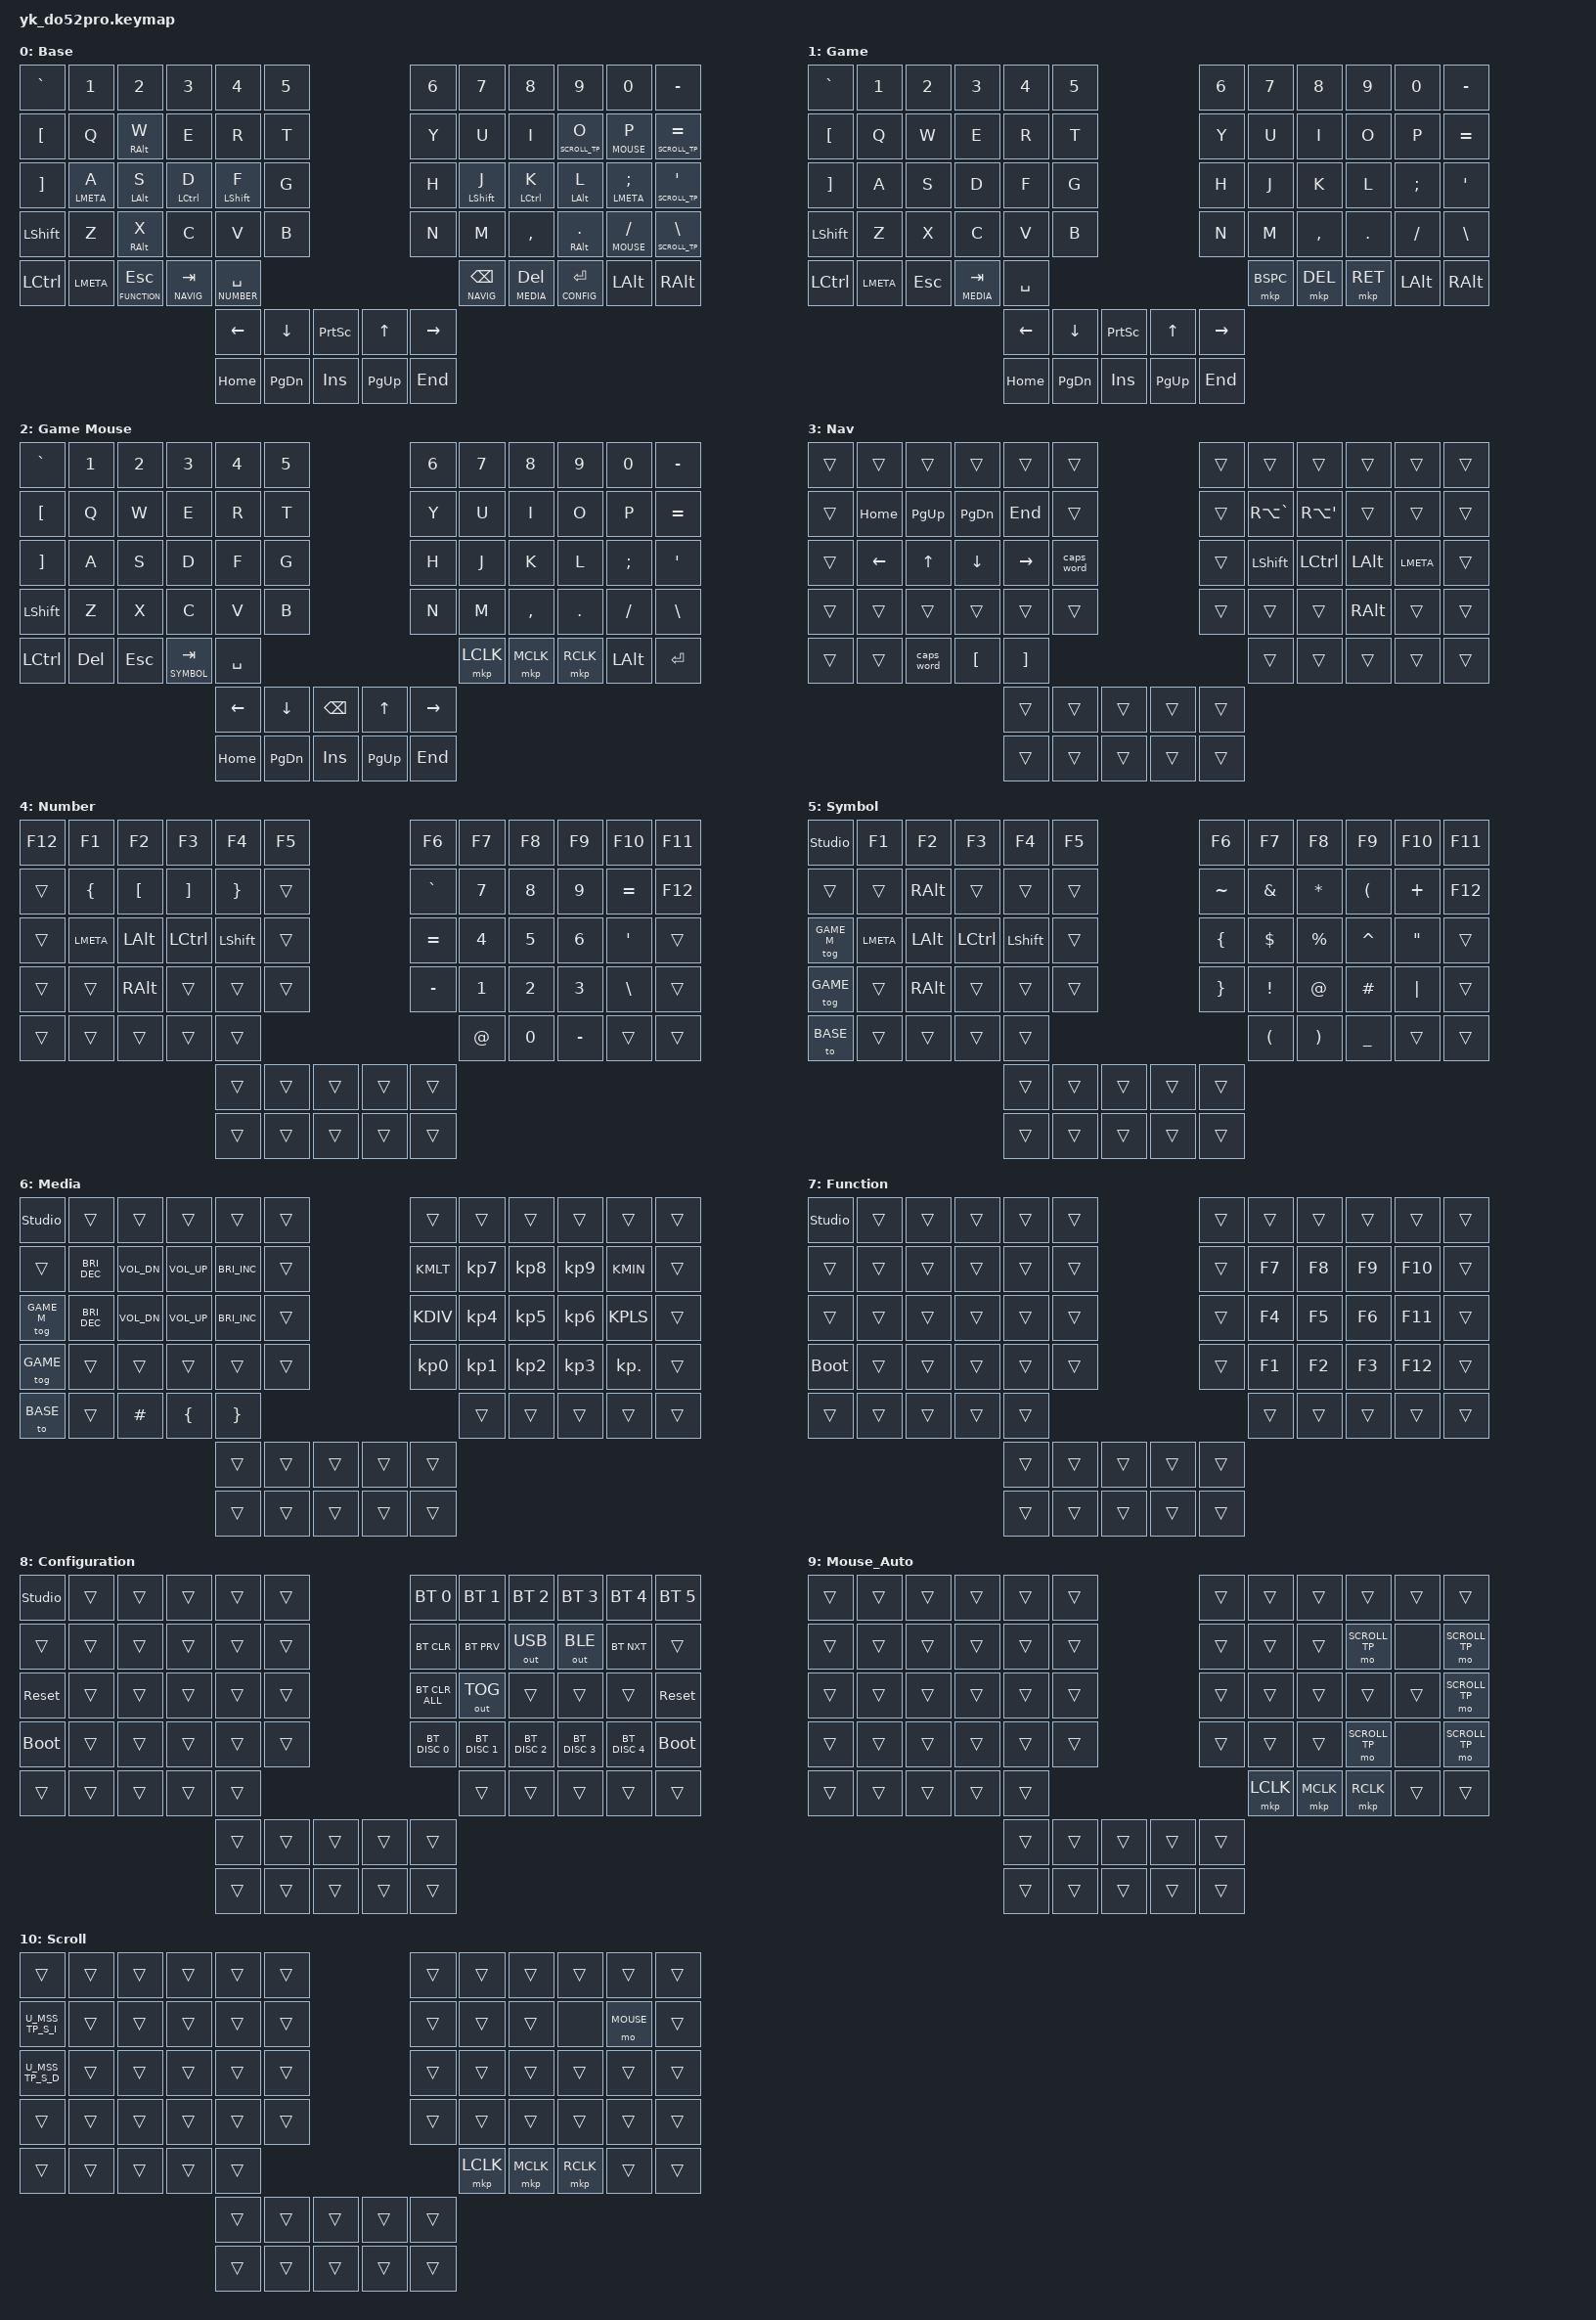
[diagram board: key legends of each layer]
/*
 * Copyright (c) 2020 The ZMK Contributors
 *
 * SPDX-License-Identifier: MIT
 */

#include <behaviors.dtsi>
#include <dt-bindings/zmk/keys.h>

#include "zmk-helpers/helper.h"
#include "include/yk_do52_key.h"                                     

#include <dt-bindings/zmk/bt.h>
#include <dt-bindings/zmk/ext_power.h>
#include <dt-bindings/zmk/outputs.h>


/*
 * Defines to enable/disable features
 *
 * These defines allow us to conditionally enable and disable parts of the keymap config.
 *
 * For example, if we decide to build the firmware without the mouse features, we can
 * disable all the config options that rely on those forks and modules without having
 * to edit the entire keymap file manually every time.
 */

#define HAS_MOUSE_KEYS
#define HAS_MOUSE_TP

#define BASE      0
#define GAME      1
#define GAME_M    2
#define NAVIG     3
#define NUMBER    4
#define SYMBOL    5
#define MEDIA     6
#define FUNCTION  7
#define CONFIG    8
#define MOUSE     9
#define SCROLL_TP 10

#ifdef HAS_MOUSE_KEYS
  #include <dt-bindings/zmk/mouse.h>
  #include <behaviors/mouse_keys.dtsi>
#endif  // HAS_MOUSE_KEYS

#ifdef HAS_MOUSE_TP
  // We store the trackpoint settings in a separate file
  // to make organization a little easier.
  #include "include/mouse_tp.dtsi"
#endif  // HAS_MOUSE_TP

// key-position labels
#define KEYS_L LT0 LT1 LT2 LT3 LT4 LM0 LM1 LM2 LM3 LM4 LB0 LB1 LB2 LB3 LB4  // left-hand keys
#define KEYS_R RT0 RT1 RT2 RT3 RT4 RM0 RM1 RM2 RM3 RM4 RB0 RB1 RB2 RB3 RB4  // right-hand keys
#define THUMBS LH4 LH3 LH2 LH1 LH0 RH0 RH1 RH2 RH3 RH4                      // thumb keys


// Adjust layer keys based on enabled features.
//
// This prevents build errors when we build the firmware
// without the mouse keys PR or the TP module.
#ifdef HAS_MOUSE_KEYS
  #define U_THUMB_INNER &mo MOUSE_KEYS
#else
  #define U_THUMB_INNER &none
#endif  // HAS_MOUSE_KEYS

#ifdef HAS_MOUSE_TP
  #define U_TOG_TP_SET &tog MOUSE_TP_SET
#else
  #define U_TOG_TP_SET &none
#endif  // HAS_MOUSE_TP


#define QUICK_TAP_MS 250


// Disable line-wrap in your editor to see a "visualization" of the key layouts
/ {

  
  behaviors {
       /* left-hand HRMs */
        hml: homerow_mods_left {
            compatible = "zmk,behavior-hold-tap";
            flavor = "balanced";
            tapping-term-ms = <280>;
            quick-tap-ms = <QUICK_TAP_MS>;                // repeat on tap-into-hold
            require-prior-idle-ms = <150>;
            #binding-cells = <2>;
            bindings = <&kp>, <&kp>;
            hold-trigger-key-positions = <KEYS_R THUMBS>;
            hold-trigger-on-release;             // delay positional check until key-release
        };

        /* right-hand HRMs */
        hmr: homerow_mods_right {
            compatible = "zmk,behavior-hold-tap";
            flavor = "balanced";
            tapping-term-ms = <280>;
            quick-tap-ms = <QUICK_TAP_MS>;                // repeat on tap-into-hold
            require-prior-idle-ms = <150>;
            #binding-cells = <2>;
            bindings = <&kp>, <&kp>;
            hold-trigger-key-positions = <KEYS_L THUMBS>;
            hold-trigger-on-release;             // delay positional check until key-release
        };
        tl: thumb_layer {
            compatible = "zmk,behavior-hold-tap";
             flavor = "balanced";
            tapping-term-ms = <280>;
            quick-tap-ms = <QUICK_TAP_MS>;                // repeat on tap-into-hold
            require-prior-idle-ms = <150>;
            #binding-cells = <2>;
            bindings = <&mo>, <&kp>;
            hold-trigger-on-release;             // delay positional check until key-release
        };       
  };
  //0
  keymap {
    compatible = "zmk,keymap";
   
    Base_layer {
      display-name = "Base";
      bindings = <
//|-----------------|-------------|-----------|------------|-----------------|----------------|---------------|   |---------------|---------------|-------------|------------|---------------|---------------|-------------|
   &kp GRAVE         &kp N1        &kp N2      &kp N3       &kp N4            &kp N5                                               &kp N6          &kp N7        &kp N8       &kp N9          &kp N0          &kp MINUS
   &kp LBKT          &kp Q         &hml RALT W &kp E        &kp R             &kp T                                                &kp Y           &kp U         &kp I        &tl SCROLL_TP O &tl MOUSE P     &tl SCROLL_TP EQUAL
   &kp RBKT          &hml LMETA A  &hml LALT S &hml LCTRL D &hml LSHIFT F     &kp G                                                &kp H           &hml LSHIFT J &hmr LCTRL K &hmr LALT L     &hmr LMETA SEMI &tl SCROLL_TP SQT
   &kp LSHFT         &kp Z         &hml RALT X &kp C        &kp V             &kp B                                                &kp N           &kp M         &kp COMMA    &hmr RALT DOT   &tl MOUSE FSLH  &tl SCROLL_TP BSLH
   &kp LCTRL         &kp LMETA                              &tl FUNCTION ESC  &tl NAVIG TAB   &tl NUMBER SPACE    &tl NAVIG BSPC  &tl MEDIA DEL   &tl CONFIG RET                             &kp LALT        &kp RALT
                                             // DPAD  Left,     Down,      Middle,     Up,        Right
                                                      &kp LEFT  &kp DOWN   &kp PSCRN   &kp UP     &kp RIGHT
                                                      &kp HOME  &kp PG_DN  &kp INS     &kp PG_UP  &kp END
      >;
    };
//1
      Game_layer {
      display-name = "Game";
      bindings = <
//|-----------------|-------------|-----------|------------|-----------------|----------------|--------------|   |---------------|---------------|-------------|-----------|-------------|---------------|------------|
   &kp GRAVE         &kp N1        &kp N2      &kp N3       &kp N4            &kp N5                                              &kp N6          &kp N7        &kp N8       &kp N9          &kp N0          &kp MINUS
   &kp LBKT          &kp Q         &kp W       &kp E        &kp R             &kp T                                               &kp Y           &kp U         &kp I        &kp O           &kp P           &kp EQUAL
   &kp RBKT          &kp A         &kp S       &kp D        &kp F             &kp G                                               &kp H           &kp J         &kp K        &kp L           &kp SEMI        &kp SQT
   &kp LSHFT         &kp Z         &kp X       &kp C        &kp V             &kp B                                               &kp N           &kp M         &kp COMMA    &kp DOT         &kp FSLH        &kp BSLH
   &kp LCTRL         &kp LMETA                              &kp ESC           &tl MEDIA TAB   &kp SPACE           &mkp BSPC      &mkp DEL        &mkp RET                                   &kp LALT        &kp RALT
                                             // DPAD  Left,     Down,      Middle,     Up,        ,Right
                                                      &kp LEFT  &kp DOWN   &kp PSCRN   &kp UP     &kp RIGHT
                                                      &kp HOME  &kp PG_DN  &kp INS     &kp PG_UP  &kp END
      >;
    };
//2
      GameMouse_layer {
      display-name = "Game Mouse";
      bindings = <
//|-----------------|-------------|-----------|------------|-----------------|----------------|--------------|   |---------------|---------------|-------------|-----------|-------------|---------------|------------|
   &kp GRAVE         &kp N1        &kp N2      &kp N3       &kp N4            &kp N5                                              &kp N6          &kp N7        &kp N8       &kp N9          &kp N0          &kp MINUS
   &kp LBKT          &kp Q         &kp W       &kp E        &kp R             &kp T                                               &kp Y           &kp U         &kp I        &kp O           &kp P           &kp EQUAL
   &kp RBKT          &kp A         &kp S       &kp D        &kp F             &kp G                                               &kp H           &kp J         &kp K        &kp L           &kp SEMI        &kp SQT
   &kp LSHFT         &kp Z         &kp X       &kp C        &kp V             &kp B                                               &kp N           &kp M         &kp COMMA    &kp DOT         &kp FSLH        &kp BSLH
   &kp LCTRL         &kp DEL                                &kp ESC           &tl SYMBOL TAB   &kp SPACE           &mkp LCLK      &mkp MCLK       &mkp RCLK                                  &kp LALT        &kp RET
                                             // DPAD  Left,     Down,      Middle,     Up,       ,Right
                                                      &kp LEFT  &kp DOWN   &kp BSPC    &kp UP     &kp RIGHT
                                                      &kp HOME  &kp PG_DN  &kp INS     &kp PG_UP  &kp END
      >;
    };
//3
    Nav_layer {
      display-name = "Nav";
         bindings = <
//|------------|-------------|-----------|-----------|---------------|---------------|---------------|   |---------------|---------------|-------------|-----------|-------------|---------------|------------|
   &trans       &trans        &trans      &trans      &trans          &trans                                              &trans          &trans        &trans      &trans        &trans          &trans
   &trans       &kp HOME      &kp PG_UP   &kp PG_DN   &kp END         &trans                                              &trans          &kp RA(GRAVE) &kp RA(SQT) &trans        &trans          &trans
   &trans       &kp LEFT      &kp UP      &kp DOWN    &kp RIGHT       &caps_word                                          &trans          &kp LSHIFT    &kp LCTRL   &kp LALT      &kp LMETA       &trans
   &trans       &trans        &trans      &trans      &trans          &trans                                              &trans          &trans        &trans      &kp RALT      &trans          &trans
   &trans       &trans                                &caps_word      &kp LBKT        &kp RBKT            &trans          &trans          &trans                                  &trans          &trans 
                                        // DPAD Left,      Down,   Middle,     Up,     Right
                                                &trans     &trans  &trans      &trans  &trans  
                                                &trans     &trans  &trans      &trans  &trans 
      >;
    };
//4
    Num_layer {
      display-name = "Number";
        bindings = <
//|------------|-------------|-----------|-----------|---------------|---------------|---------------|   |---------------|---------------|-------------|-------------|-------------|---------------|------------|
   &kp F12      &kp F1        &kp F2      &kp F3      &kp F4          &kp F5                                              &kp F6          &kp F7        &kp F8        &kp F9        &kp F10         &kp F11         
   &trans       &kp LBRC      &kp LBKT    &kp RBKT    &kp RBRC        &trans                                              &kp GRAVE       &kp NUMBER_7  &kp NUMBER_8  &kp NUMBER_9  &kp EQUAL       &kp F12
   &trans       &kp LMETA     &kp LALT    &kp LCTRL   &kp LSHIFT      &trans                                              &kp EQUAL       &kp NUMBER_4  &kp NUMBER_5  &kp NUMBER_6  &kp SQT         &trans
   &trans       &trans        &kp RALT    &trans      &trans          &trans                                              &kp MINUS       &kp NUMBER_1  &kp NUMBER_2  &kp NUMBER_3  &kp BSLH        &trans
   &trans       &trans                                &trans          &trans          &trans               &kp AT         &kp NUMBER_0    &kp MINUS                                 &trans          &trans 
                                        // DPAD Left,      Down,   Middle,     Up,     Right
                                                &trans     &trans  &trans      &trans  &trans  
                                                &trans     &trans  &trans      &trans  &trans 
      >;
    };

  //5
    Symb_layer {
      display-name = "Symbol";
          bindings = <
//|--------------|-------------|-----------|-----------|---------------|---------------|---------------|   |---------------|---------------|-------------|-----------|-------------|---------------|------------|
   &studio_unlock &kp F1        &kp F2      &kp F3      &kp F4          &kp F5                                              &kp F6          &kp F7        &kp F8        &kp F9        &kp F10         &kp F11
   &trans         &trans        &kp RALT    &trans      &trans          &trans                                              &kp TILDE       &kp AMPERSAND &kp STAR      &kp LPAR      &kp PLUS        &kp F12
   &tog GAME_M    &kp LMETA     &kp LALT    &kp LCTRL   &kp LSHIFT      &trans                                              &kp LBRC        &kp DOLLAR    &kp PERCENT   &kp CARET     &kp DQT         &trans
   &tog GAME      &trans        &kp RALT    &trans      &trans          &trans                                              &kp RBRC        &kp EXCL      &kp AT        &kp HASH      &kp PIPE        &trans
   &to BASE       &trans                                &trans          &trans          &trans              &kp LPAR        &kp RPAR        &kp UNDER                                 &trans          &trans 
                                          // DPAD Left,      Down,   Middle,     Up,     Right
                                                &trans     &trans  &trans      &trans  &trans  
                                                &trans     &trans  &trans      &trans  &trans
      >;
    };
 //6
  Media_layer {
      display-name = "Media";
         bindings = <
//|--------------|-------------|-------------|-------------|---------------|---------------|---------------|   |---------------|---------------|-------------|-----------|-------------|---------------|------------|
   &studio_unlock &trans        &trans        &trans        &trans          &trans                                              &trans          &trans        &trans      &trans        &trans          &trans
   &trans         &kp C_BRI_DEC &kp C_VOL_DN  &kp C_VOL_UP  &kp C_BRI_INC   &trans                                              &kp KMLT        &kp KP_N7     &kp KP_N8   &kp KP_N9     &kp KMIN        &trans
   &tog GAME_M    &kp C_BRI_DEC &kp C_VOL_DN  &kp C_VOL_UP  &kp C_BRI_INC   &trans                                              &kp KDIV        &kp KP_N4     &kp KP_N5   &kp KP_N6     &kp KPLS        &trans
   &tog GAME      &trans        &trans        &trans        &trans          &trans                                              &kp KP_N0       &kp KP_N1     &kp KP_N2   &kp KP_N3     &kp KP_DOT      &trans
   &to BASE       &trans                                    &kp HASH        &kp LBRC        &kp RBRC             &trans         &trans          &trans                                  &trans          &trans
                                        // DPAD Left,      Down,   Middle,     Up,     Right
                                                &trans     &trans  &trans      &trans  &trans  
                                                &trans     &trans  &trans      &trans  &trans 
      >;
    };

    
//7
    Func_layer {
      display-name = "Function";
      bindings = <
//|-----------------|-------------|-----------|-----------|---------------|---------------|---------------|   |---------------|---------------|-------------|-----------|-------------|---------------|------------|
   &studio_unlock    &trans        &trans      &trans      &trans          &trans                                              &trans          &trans        &trans      &trans        &trans          &trans
   &trans            &trans        &trans      &trans      &trans          &trans                                              &trans          &kp F7        &kp F8      &kp F9        &kp F10         &trans
   &trans            &trans        &trans      &trans      &trans          &trans                                              &trans          &kp F4        &kp F5      &kp F6        &kp F11         &trans
   &bootloader       &trans        &trans      &trans      &trans          &trans                                              &trans          &kp F1        &kp F2      &kp F3        &kp F12         &trans
   &trans            &trans                                &trans          &trans          &trans              &trans          &trans          &trans                                  &trans          &trans 
                                        // DPAD Left,      Down,   Middle,     Up,     Right
                                                &trans     &trans  &trans      &trans  &trans 
                                                &trans     &trans  &trans      &trans  &trans
      >;
    };
//8
    Config_layer {
      display-name = "Configuration";
      bindings = <
//|---------------|-------------|-----------|-----------|---------------|---------------|---------------|   |---------------|---------------|-------------|-------------|-------------|---------------|------------|
   &studio_unlock  &trans        &trans      &trans      &trans          &trans                                              &bt BT_SEL 0    &bt BT_SEL 1  &bt BT_SEL 2  &bt BT_SEL 3  &bt BT_SEL 4    &bt BT_SEL 5
   &trans          &trans        &trans      &trans      &trans          &trans                                              &bt BT_CLR      &bt BT_PRV    &out OUT_USB  &out OUT_BLE  &bt BT_NXT      &trans
   &sys_reset      &trans        &trans      &trans      &trans          &trans                                              &bt BT_CLR_ALL  &out OUT_TOG  &trans        &trans        &trans          &sys_reset
   &bootloader     &trans        &trans      &trans      &trans          &trans                                              &bt BT_DISC 0   &bt BT_DISC 1 &bt BT_DISC 2 &bt BT_DISC 3 &bt BT_DISC 4   &bootloader
   &trans          &trans                                &trans          &trans          &trans              &trans          &trans          &trans                                    &trans          &trans 
                                        // DPAD Left,      Down,   Middle,     Up,     Right
                                                &trans     &trans  &trans      &trans  &trans  
                                                &trans     &trans  &trans      &trans  &trans 
      >;
    };

   //9
     Mouse_layerAuto {
      display-name = "Mouse_Auto";
      bindings = <
//|------------|-------------|-----------|-----------|---------------|---------------|---------------|   |---------------|---------------|-------------|-----------|---------------|---------------|------------|
   &trans       &trans        &trans      &trans      &trans          &trans                                              &trans          &trans        &trans      &trans          &trans          &trans
   &trans       &trans        &trans      &trans      &trans          &trans                                              &trans          &trans        &trans      &mo SCROLL_TP   &none           &mo SCROLL_TP
   &trans       &trans        &trans      &trans      &trans          &trans                                              &trans          &trans        &trans      &trans          &trans          &mo SCROLL_TP
   &trans       &trans        &trans      &trans      &trans          &trans                                              &trans          &trans        &trans      &mo SCROLL_TP   &none           &mo SCROLL_TP
   &trans       &trans                                &trans          &trans          &trans               &mkp LCLK      &mkp MCLK       &mkp RCLK                                 &trans          &trans 
                                           // DPAD Left,      Down,   Middle,     Up,     Right
                                                   &trans     &trans  &trans      &trans  &trans
                                                   &trans     &trans  &trans      &trans  &trans
         >;
       };

//10'
     Scroll_layer {
      display-name = "Scroll";
      bindings = <
//|-------------|-------------|-----------|-----------|---------------|---------------|---------------|   |---------------|---------------|-------------|-----------|-------------|---------------|------------|
   &trans        &trans        &trans      &trans      &trans          &trans                                              &trans          &trans        &trans      &trans        &trans          &trans
   U_MSS_TP_S_I  &trans        &trans      &trans      &trans          &trans                                              &trans          &trans        &trans      &none         &mo MOUSE       &trans
   U_MSS_TP_S_D  &trans        &trans      &trans      &trans          &trans                                              &trans          &trans        &trans      &trans        &trans          &trans
   &trans        &trans        &trans      &trans      &trans          &trans                                              &trans          &trans        &trans      &trans        &trans          &trans
   &trans        &trans                                &trans          &trans          &trans               &mkp LCLK      &mkp MCLK       &mkp RCLK                               &trans          &trans 
                                        // DPAD Left,      Down,   Middle,     Up,     Right
                                                &trans     &trans  &trans      &trans  &trans  
                                                &trans     &trans  &trans      &trans  &trans           
      >;
    };




#ifdef HAS_MOUSE_KEYS

#endif
#ifdef HAS_MOUSE_TP
//         // You can find the defines for the actual key press behaviors in `include/mouse_tp.dtsi`.
//         MouseSettings_layer {
//           display-name = "TP Set";
//           bindings = <
//     // ╭────────────────────────┬────────────────────────┬────────────────────────┬────────────────────────┬────────────────────────┬────────────────────────╮    ╭────────────────────────┬────────────────────────┬────────────────────────┬────────────────────────┬────────────────────────┬────────────────────────╮
//          U_TOG_TP_SET             U_TOG_TP_SET             &none                    U_MSS_TP_S_D             U_MSS_TP_S_I             U_MSS_TP_PT_I                 U_MSS_TP_PT_I            U_MSS_TP_S_D             U_MSS_TP_S_I             &none                    U_TOG_TP_SET              U_TOG_TP_SET
//     // ├────────────────────────┼────────────────────────┼────────────────────────┼────────────────────────┼────────────────────────┼────────────────────────┤    ├────────────────────────┼────────────────────────┼────────────────────────┼────────────────────────┼────────────────────────┼────────────────────────┤
//          U_MSS_RESET              U_MSS_RESET              &none                    U_MSS_TP_NI_D            U_MSS_TP_NI_I            U_MSS_TP_PT_D                 U_MSS_TP_PT_D            U_MSS_TP_NI_D            U_MSS_TP_NI_I            &none                    U_MSS_RESET               U_MSS_RESET
//     // ├────────────────────────┼────────────────────────┼────────────────────────┼────────────────────────┼────────────────────────┼────────────────────────┤    ├────────────────────────┼────────────────────────┼────────────────────────┼────────────────────────┼────────────────────────┼────────────────────────┤
//          U_MSS_LOG                U_MSS_LOG                &none                    U_MSS_TP_V6_D            U_MSS_TP_V6_I            &none                         &none                    U_MSS_TP_V6_D            U_MSS_TP_V6_I            &none                    U_MSS_LOG                 U_MSS_LOG
//     // ╰────────────────────────┴────────────────────────┴────────────────────────┴────────────────────────┼────────────────────────┼────────────────────────┤    ├────────────────────────┼────────────────────────┼────────────────────────┼────────────────────────┴────────────────────────┼────────────────────────╯
//                                                                                     &trans                   &mkp LCLK                &mkp RCLK                     &none                    &mkp LCLK                &mkp RCLK
//     //                                                                            ╰────────────────────────┴────────────────────────┴────────────────────────╯    ╰────────────────────────┴────────────────────────┴────────────────────────╯
//           >;
//         };


#endif

 

  };
};









































